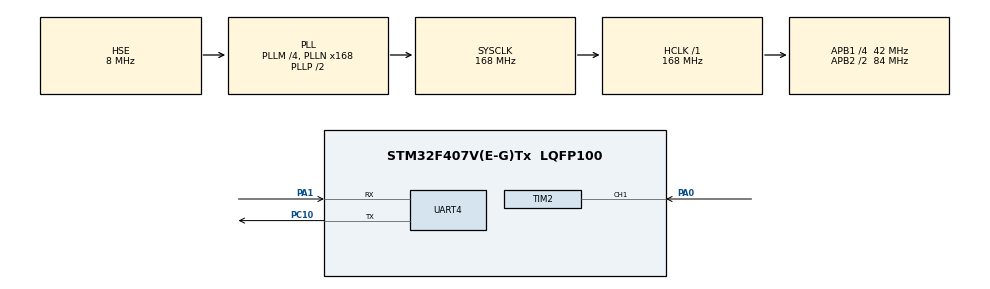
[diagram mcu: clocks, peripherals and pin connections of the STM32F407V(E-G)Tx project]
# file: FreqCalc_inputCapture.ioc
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Mcu.Family=STM32F4
Mcu.Name=STM32F407V(E-G)Tx
Mcu.Package=LQFP100
NVIC.PriorityGroup=NVIC_PRIORITYGROUP_0
NVIC.TIM2_IRQn=true\:0\:0\:false\:false\:true\:true\:true\:true
NVIC.TIM3_IRQn=true\:0\:0\:false\:false\:true\:true\:true\:true
PA0-WKUP.Signal=S_TIM2_CH1_ETR
PA1.Mode=Asynchronous
PA1.Signal=UART4_RX
PA13.Mode=Serial_Wire
PA13.Signal=SYS_JTMS-SWDIO
PA14.Mode=Serial_Wire
PA14.Signal=SYS_JTCK-SWCLK
PC10.Mode=Asynchronous
PC10.Signal=UART4_TX
PH0-OSC_IN.Mode=HSE-External-Oscillator
PH0-OSC_IN.Signal=RCC_OSC_IN
PH1-OSC_OUT.Mode=HSE-External-Oscillator
PH1-OSC_OUT.Signal=RCC_OSC_OUT
ProjectManager.HeapSize=0x200
ProjectManager.StackSize=0x400
ProjectManager.TargetToolchain=STM32CubeIDE
RCC.48MHZClocksFreq_Value=48000000
RCC.AHBFreq_Value=168000000
RCC.APB1CLKDivider=RCC_HCLK_DIV4
RCC.APB1Freq_Value=42000000
RCC.APB1TimFreq_Value=84000000
RCC.APB2CLKDivider=RCC_HCLK_DIV2
RCC.APB2Freq_Value=84000000
RCC.APB2TimFreq_Value=168000000
RCC.CortexFreq_Value=168000000
RCC.HCLKFreq_Value=168000000
RCC.HSE_VALUE=8000000
RCC.HSI_VALUE=16000000
RCC.LSE_VALUE=32768
RCC.PLLM=4
RCC.PLLN=168
RCC.PLLQ=7
RCC.PLLSourceVirtual=RCC_PLLSOURCE_HSE
RCC.SYSCLKFreq_VALUE=168000000
RCC.SYSCLKSource=RCC_SYSCLKSOURCE_PLLCLK
RCC.VCOOutputFreq_Value=336000000
SH.S_TIM2_CH1_ETR.0=TIM2_CH1,Input_Capture1_from_TI1
TIM2.Channel-Input_Capture1_from_TI1=TIM_CHANNEL_1
TIM3.Period=1000 - 1
TIM3.Prescaler=8400 - 1
UART4.VirtualMode=Asynchronous
VP_TIM2_VS_ClockSourceINT.Mode=Internal
VP_TIM3_VS_ClockSourceINT.Mode=Internal
board=STM32F407G-DISC1

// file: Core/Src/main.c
/* USER CODE BEGIN Header */
/**
  ******************************************************************************
  * @file           : main.c
  * @brief          : Main program body
  ******************************************************************************
  * @attention
  *
  * Copyright (c) 2025 STMicroelectronics.
  * All rights reserved.
  *
  * This software is licensed under terms that can be found in the LICENSE file
  * in the root directory of this software component.
  * If no LICENSE file comes with this software, it is provided AS-IS.
  *
  ******************************************************************************
  */
/* USER CODE END Header */
#include "main.h"
#include "stdio.h"

TIM_HandleTypeDef htim2;
TIM_HandleTypeDef htim3;

UART_HandleTypeDef huart4;

/* USER CODE BEGIN PV */
float frequency = 0.0;
uint8_t is1st_capture = 1;
uint32_t val1 = 0, val2 = 0, difference = 0;
float refClock = 84000000.0; // as tim2(APB1) clock is at 84 MHz
uint32_t freq_buffer[100];
uint8_t tx_buffer[20];
uint8_t freq_Use = 0;
uint32_t avg_freq;
uint8_t index = 0;
/* USER CODE END PV */

void SystemClock_Config(void);
static void MX_GPIO_Init(void);
static void MX_TIM2_Init(void);
static void MX_UART4_Init(void);
static void MX_TIM3_Init(void);

/* USER CODE BEGIN 0 */
void HAL_TIM_IC_CaptureCallback(TIM_HandleTypeDef *htim)
{
	if(htim->Instance == TIM2 && htim->Channel == HAL_TIM_ACTIVE_CHANNEL_1)
	{
		if(is1st_capture)
		{
			is1st_capture = 0;
			val1 = HAL_TIM_ReadCapturedValue(&htim2, TIM_CHANNEL_1);	// reading first rising edge
		}
		else
		{
			val2 = HAL_TIM_ReadCapturedValue(&htim2, TIM_CHANNEL_1);	// reading 2nd rising edge
			if(val2 >= val1)
			{
				difference = val2 - val1;
			}
			else if(val2 < val1)
			{
				difference = (0xffffffff - val1) + val2;
			}

			frequency = refClock / difference;

			__HAL_TIM_SET_COUNTER(htim, 0);								// resetting counter
			is1st_capture = 1;
			freq_Use = 1;
		}
	}
}
void HAL_TIM_PeriodElapsedCallback(TIM_HandleTypeDef *htim)
{
	if(htim->Instance == TIM3 && freq_Use)
	{
		freq_Use = 0;

		// Store frequency in buffer
		freq_buffer[index] = frequency;
		index = (index + 1) % 100;

		// Calculate moving average
		uint64_t sum = 0;
		for(uint8_t i = 0; i < 100; i++)
			sum += freq_buffer[i];
		avg_freq = sum / 100;
	}
}
/* USER CODE END 0 */

int main(void)
{

  /* MCU Configuration--------------------------------------------------------*/

  /* Reset of all peripherals, Initializes the Flash interface and the Systick. */
  HAL_Init();

  /* Configure the system clock */
  SystemClock_Config();

  /* Initialize all configured peripherals */
  MX_GPIO_Init();
  MX_TIM2_Init();
  MX_UART4_Init();
  MX_TIM3_Init();
  /* USER CODE BEGIN 2 */
  for(uint8_t i = 0; i < 100; i++)
  {
	  freq_buffer[i] = 0;
  }
  HAL_TIM_IC_Start_IT(&htim2, TIM_CHANNEL_1);	// Start input capture
  HAL_TIM_Base_Start_IT(&htim3);				// Start TIM3 periodic timer
  /* USER CODE END 2 */

  /* Infinite loop */
  while (1)
  {
	// Send via UART
	int len = sprintf((char*)tx_buffer, "%lu Hz\r\n", avg_freq);
	HAL_UART_Transmit(&huart4, tx_buffer, len, 100);
	HAL_Delay(1000/2);
  }
}

void SystemClock_Config(void)
{
  RCC_OscInitTypeDef RCC_OscInitStruct = {0};
  RCC_ClkInitTypeDef RCC_ClkInitStruct = {0};

  /** Configure the main internal regulator output voltage
  */
  __HAL_RCC_PWR_CLK_ENABLE();
  __HAL_PWR_VOLTAGESCALING_CONFIG(PWR_REGULATOR_VOLTAGE_SCALE1);

  /** Initializes the RCC Oscillators according to the specified parameters
  * in the RCC_OscInitTypeDef structure.
  */
  RCC_OscInitStruct.OscillatorType = RCC_OSCILLATORTYPE_HSE;
  RCC_OscInitStruct.HSEState = RCC_HSE_ON;
  RCC_OscInitStruct.PLL.PLLState = RCC_PLL_ON;
  RCC_OscInitStruct.PLL.PLLSource = RCC_PLLSOURCE_HSE;
  RCC_OscInitStruct.PLL.PLLM = 4;
  RCC_OscInitStruct.PLL.PLLN = 168;
  RCC_OscInitStruct.PLL.PLLP = RCC_PLLP_DIV2;
  RCC_OscInitStruct.PLL.PLLQ = 7;
  if (HAL_RCC_OscConfig(&RCC_OscInitStruct) != HAL_OK)
  {
    Error_Handler();
  }

  /** Initializes the CPU, AHB and APB buses clocks
  */
  RCC_ClkInitStruct.ClockType = RCC_CLOCKTYPE_HCLK|RCC_CLOCKTYPE_SYSCLK
                              |RCC_CLOCKTYPE_PCLK1|RCC_CLOCKTYPE_PCLK2;
  RCC_ClkInitStruct.SYSCLKSource = RCC_SYSCLKSOURCE_PLLCLK;
  RCC_ClkInitStruct.AHBCLKDivider = RCC_SYSCLK_DIV1;
  RCC_ClkInitStruct.APB1CLKDivider = RCC_HCLK_DIV4;
  RCC_ClkInitStruct.APB2CLKDivider = RCC_HCLK_DIV2;

  if (HAL_RCC_ClockConfig(&RCC_ClkInitStruct, FLASH_LATENCY_5) != HAL_OK)
  {
    Error_Handler();
  }
}

static void MX_TIM2_Init(void)
{

  TIM_ClockConfigTypeDef sClockSourceConfig = {0};
  TIM_MasterConfigTypeDef sMasterConfig = {0};
  TIM_IC_InitTypeDef sConfigIC = {0};

  htim2.Instance = TIM2;
  htim2.Init.Prescaler = 0;
  htim2.Init.CounterMode = TIM_COUNTERMODE_UP;
  htim2.Init.Period = 4294967295;
  htim2.Init.ClockDivision = TIM_CLOCKDIVISION_DIV1;
  htim2.Init.AutoReloadPreload = TIM_AUTORELOAD_PRELOAD_DISABLE;
  if (HAL_TIM_Base_Init(&htim2) != HAL_OK)
  {
    Error_Handler();
  }
  sClockSourceConfig.ClockSource = TIM_CLOCKSOURCE_INTERNAL;
  if (HAL_TIM_ConfigClockSource(&htim2, &sClockSourceConfig) != HAL_OK)
  {
    Error_Handler();
  }
  if (HAL_TIM_IC_Init(&htim2) != HAL_OK)
  {
    Error_Handler();
  }
  sMasterConfig.MasterOutputTrigger = TIM_TRGO_RESET;
  sMasterConfig.MasterSlaveMode = TIM_MASTERSLAVEMODE_DISABLE;
  if (HAL_TIMEx_MasterConfigSynchronization(&htim2, &sMasterConfig) != HAL_OK)
  {
    Error_Handler();
  }
  sConfigIC.ICPolarity = TIM_INPUTCHANNELPOLARITY_RISING;
  sConfigIC.ICSelection = TIM_ICSELECTION_DIRECTTI;
  sConfigIC.ICPrescaler = TIM_ICPSC_DIV1;
  sConfigIC.ICFilter = 0;
  if (HAL_TIM_IC_ConfigChannel(&htim2, &sConfigIC, TIM_CHANNEL_1) != HAL_OK)
  {
    Error_Handler();
  }

}

static void MX_TIM3_Init(void)
{

  TIM_ClockConfigTypeDef sClockSourceConfig = {0};
  TIM_MasterConfigTypeDef sMasterConfig = {0};

  htim3.Instance = TIM3;
  htim3.Init.Prescaler = 8400 - 1;
  htim3.Init.CounterMode = TIM_COUNTERMODE_UP;
  htim3.Init.Period = 100 - 1;
  htim3.Init.ClockDivision = TIM_CLOCKDIVISION_DIV1;
  htim3.Init.AutoReloadPreload = TIM_AUTORELOAD_PRELOAD_DISABLE;
  if (HAL_TIM_Base_Init(&htim3) != HAL_OK)
  {
    Error_Handler();
  }
  sClockSourceConfig.ClockSource = TIM_CLOCKSOURCE_INTERNAL;
  if (HAL_TIM_ConfigClockSource(&htim3, &sClockSourceConfig) != HAL_OK)
  {
    Error_Handler();
  }
  sMasterConfig.MasterOutputTrigger = TIM_TRGO_RESET;
  sMasterConfig.MasterSlaveMode = TIM_MASTERSLAVEMODE_DISABLE;
  if (HAL_TIMEx_MasterConfigSynchronization(&htim3, &sMasterConfig) != HAL_OK)
  {
    Error_Handler();
  }

}

static void MX_UART4_Init(void)
{

  huart4.Instance = UART4;
  huart4.Init.BaudRate = 115200;
  huart4.Init.WordLength = UART_WORDLENGTH_8B;
  huart4.Init.StopBits = UART_STOPBITS_1;
  huart4.Init.Parity = UART_PARITY_NONE;
  huart4.Init.Mode = UART_MODE_TX_RX;
  huart4.Init.HwFlowCtl = UART_HWCONTROL_NONE;
  huart4.Init.OverSampling = UART_OVERSAMPLING_16;
  if (HAL_UART_Init(&huart4) != HAL_OK)
  {
    Error_Handler();
  }

}

static void MX_GPIO_Init(void)
{

  /* GPIO Ports Clock Enable */
  __HAL_RCC_GPIOH_CLK_ENABLE();
  __HAL_RCC_GPIOA_CLK_ENABLE();
  __HAL_RCC_GPIOC_CLK_ENABLE();

}

void Error_Handler(void)
{
  __disable_irq();
  while (1)
  {
  }
}
